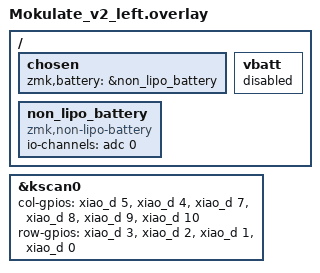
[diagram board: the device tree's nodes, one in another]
#include "Mokulate_v2.dtsi"

/ {
    chosen {
        zmk,battery = &non_lipo_battery;
    };

    // Disable default Xiao BLE battery monitoring (uses AIN7 with voltage divider)
    vbatt: vbatt {
        status = "disabled";
    };

    // Non-LiPo battery on AIN0 (D0/P0.02) - direct connection, no voltage divider
    non_lipo_battery: non_lipo_battery {
        compatible = "zmk,non-lipo-battery";
        io-channels = <&adc 0>;
    };
};

&kscan0 {
    col-gpios
        = <&xiao_d 5 GPIO_ACTIVE_HIGH>   /* Col0 */
        , <&xiao_d 4 GPIO_ACTIVE_HIGH>   /* Col1 */
        , <&xiao_d 7 GPIO_ACTIVE_HIGH>   /* Col2 */
        , <&xiao_d 8 GPIO_ACTIVE_HIGH>   /* Col3 */
        , <&xiao_d 9 GPIO_ACTIVE_HIGH>   /* Col4 */
        , <&xiao_d 10 GPIO_ACTIVE_HIGH>  /* Col5 */
        ;
    row-gpios
        = <&xiao_d 3 (GPIO_ACTIVE_HIGH | GPIO_PULL_DOWN)>  /* Row0 */
        , <&xiao_d 2 (GPIO_ACTIVE_HIGH | GPIO_PULL_DOWN)>  /* Row1 */
        , <&xiao_d 1 (GPIO_ACTIVE_HIGH | GPIO_PULL_DOWN)>  /* Row2 */
        , <&xiao_d 0 (GPIO_ACTIVE_HIGH | GPIO_PULL_DOWN)>  /* Row3 */
        ;
};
